# CBASS_MEM_CBASS_FW_45040000h register map
Vendor: Texas Instruments
Peripheral module from a debugger description file (folder AM275x).
Registers are 32-bit, read-write, reset 0x0 unless marked. A register's access mark holds for its fields unless they carry their own. Offsets are as the file gives them; lines under a group give offsets from that group; [hi:lo] are bit positions; {n}, {i} and the like mark numbered series; 'fields as' and 'values as' point back to an identical list; <NAME> marks a mode.

## cbass_fw
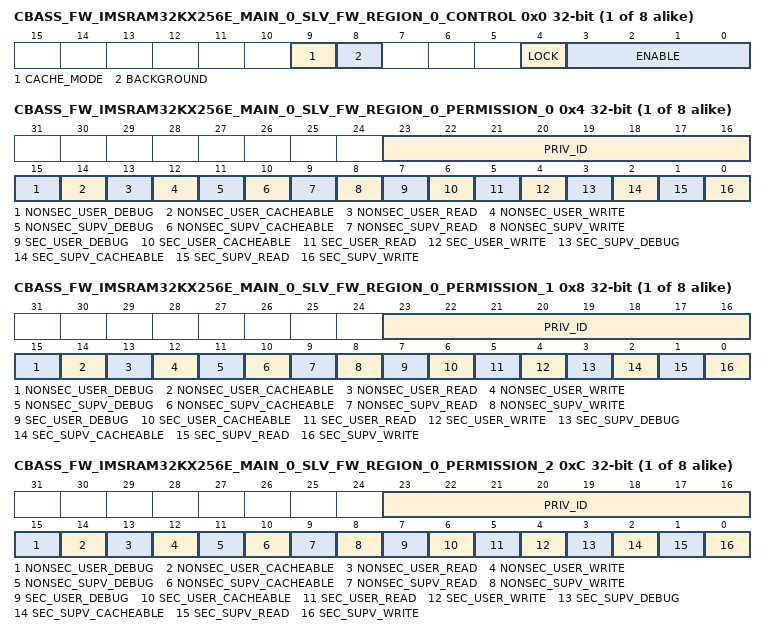
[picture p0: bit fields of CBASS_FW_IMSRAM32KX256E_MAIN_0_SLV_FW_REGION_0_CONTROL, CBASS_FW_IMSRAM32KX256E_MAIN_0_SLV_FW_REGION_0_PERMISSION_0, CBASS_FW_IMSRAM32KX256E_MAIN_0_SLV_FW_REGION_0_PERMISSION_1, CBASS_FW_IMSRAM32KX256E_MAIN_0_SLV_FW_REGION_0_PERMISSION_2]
{0x0+0x20*i} CBASS_FW_IMSRAM32KX256E_MAIN_0_SLV_FW_REGION_{i}_CONTROL access not given (i=0..7) — The FW Region {i} Control Register defines the control fields for the target Imsram32kx256e_main_0.slv region {i} firewall.
  [9] CACHE_MODE rw — Cache mode for region. Set to 1 to check cache permissions. Set to 0 to ignore cache permissions. Reset Source: domain_default_rst_mod_g_rst_n
  [8] BACKGROUND rw — Background enable for region. There can be 1 backgroun region per FW and foreground regions can have overlapping addresses only with the background region. Reset Source: domain_default_rst_mod_g_rst_n
  [4] LOCK — Lock region. Once set region values cannot be modified. Reset Source: domain_default_rst_mod_g_rst_n (access R/W1TS)
  [3:0] ENABLE rw — Enable region. A value of 0xA enables, others disable. Reset Source: domain_default_rst_mod_g_rst_n
{0x4+0x20*i} CBASS_FW_IMSRAM32KX256E_MAIN_0_SLV_FW_REGION_{i}_PERMISSION_0 (i=0..7) — The FW Region {i} Permission 0 Register defines the permissions for the target Imsram32kx256e_main_0.slv region {i} firewall.
  [23:16] PRIV_ID — Allowed privid. Reset Source: domain_default_rst_mod_g_rst_n
  [15] NONSEC_USER_DEBUG — Non-secure user debug allowed. Reset Source: domain_default_rst_mod_g_rst_n
  [14] NONSEC_USER_CACHEABLE — Non-secure user cacheable allowed. Reset Source: domain_default_rst_mod_g_rst_n
  [13] NONSEC_USER_READ — Non-secure user read allowed. Reset Source: domain_default_rst_mod_g_rst_n
  [12] NONSEC_USER_WRITE — Non-secure user write allowed. Reset Source: domain_default_rst_mod_g_rst_n
  [11] NONSEC_SUPV_DEBUG — Non-secure supervisor debug allowed. Reset Source: domain_default_rst_mod_g_rst_n
  [10] NONSEC_SUPV_CACHEABLE — Non-secure supervisor cacheable allowed. Reset Source: domain_default_rst_mod_g_rst_n
  [9] NONSEC_SUPV_READ — Non-secure supervisor read allowed. Reset Source: domain_default_rst_mod_g_rst_n
  [8] NONSEC_SUPV_WRITE — Non-secure supervisor write allowed. Reset Source: domain_default_rst_mod_g_rst_n
  [7] SEC_USER_DEBUG — Secure user debug allowed. Reset Source: domain_default_rst_mod_g_rst_n
  [6] SEC_USER_CACHEABLE — Secure user cacheable allowed. Reset Source: domain_default_rst_mod_g_rst_n
  [5] SEC_USER_READ — Secure user read allowed. Reset Source: domain_default_rst_mod_g_rst_n
  [4] SEC_USER_WRITE — Secure user write allowed. Reset Source: domain_default_rst_mod_g_rst_n
  [3] SEC_SUPV_DEBUG — Secure supervisor debug allowed. Reset Source: domain_default_rst_mod_g_rst_n
  [2] SEC_SUPV_CACHEABLE — Secure supervisor cacheable allowed. Reset Source: domain_default_rst_mod_g_rst_n
  [1] SEC_SUPV_READ — Secure supervisor read allowed. Reset Source: domain_default_rst_mod_g_rst_n
  [0] SEC_SUPV_WRITE — Secure supervisor write allowed. Reset Source: domain_default_rst_mod_g_rst_n
{0x8+0x20*i} CBASS_FW_IMSRAM32KX256E_MAIN_0_SLV_FW_REGION_{i}_PERMISSION_1 (i=0..7) — The FW Region {i} Permission 1 Register defines the permissions for the target Imsram32kx256e_main_0.slv region {i} firewall.
  fields as CBASS_FW_IMSRAM32KX256E_MAIN_0_SLV_FW_REGION_0_PERMISSION_0
{0xC+0x20*i} CBASS_FW_IMSRAM32KX256E_MAIN_0_SLV_FW_REGION_{i}_PERMISSION_2 (i=0..7) — The FW Region {i} Permission 2 Register defines the permissions for the target Imsram32kx256e_main_0.slv region {i} firewall.
  fields as CBASS_FW_IMSRAM32KX256E_MAIN_0_SLV_FW_REGION_0_PERMISSION_0
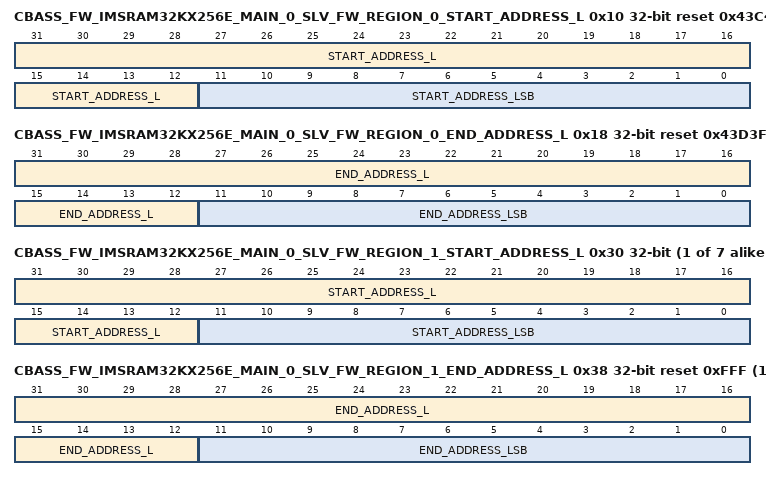
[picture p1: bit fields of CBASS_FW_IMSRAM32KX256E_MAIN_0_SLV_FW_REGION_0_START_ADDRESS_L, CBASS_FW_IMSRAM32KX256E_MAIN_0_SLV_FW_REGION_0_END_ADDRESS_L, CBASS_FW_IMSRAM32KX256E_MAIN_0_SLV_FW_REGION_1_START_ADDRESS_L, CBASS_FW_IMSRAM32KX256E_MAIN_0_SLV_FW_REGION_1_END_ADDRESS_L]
0x10 CBASS_FW_IMSRAM32KX256E_MAIN_0_SLV_FW_REGION_0_START_ADDRESS_L access per field reset 0x43C40000 — The FW Region 0 Start Address Low Register defines the start address bits 31 to 0 for the target Imsram32kx256e_main_0.slv region 0 firewall.
  [31:12] START_ADDRESS_L rw — Start address bits 31 to 12. Lowest 12 bits are forced to 0 as address must be 4KB aligned. Reset Source: domain_default_rst_mod_g_rst_n
  [11:0] START_ADDRESS_LSB ro — Start address bits 11 to 0 are forced to 0 as address must be 4KB aligned. Reset Source: domain_default_rst_mod_g_rst_n
{0x14+0x20*i} CBASS_FW_IMSRAM32KX256E_MAIN_0_SLV_FW_REGION_{i}_START_ADDRESS_H (i=0..7) — The FW Region {i} Start Address High Register defines the start address bits 47 to 32 for the target Imsram32kx256e_main_0.slv region {i} firewall.
  [15:0] START_ADDRESS_H — Start address bits 47 to 32. Reset Source: domain_default_rst_mod_g_rst_n
0x18 CBASS_FW_IMSRAM32KX256E_MAIN_0_SLV_FW_REGION_0_END_ADDRESS_L access per field reset 0x43D3FFFF — The FW Region 0 End Address Low Register defines the end address bits 31 to 0 to include for the target Imsram32kx256e_main_0.slv region 0 firewall.
  [31:12] END_ADDRESS_L rw — End address bits 31 to 12 to include in the match. Lowest 12 bits are forced to 1s as address must be 4KB aligned. Reset Source: domain_default_rst_mod_g_rst_n
  [11:0] END_ADDRESS_LSB ro — End address bits 11 to 0 are forced to 1s as address must be 4KB aligned minus 1. Reset Source: domain_default_rst_mod_g_rst_n
{0x1C+0x20*i} CBASS_FW_IMSRAM32KX256E_MAIN_0_SLV_FW_REGION_{i}_END_ADDRESS_H (i=0..7) — The FW Region {i} End Address High Register defines the end address bits 47 to 32 to include for the target Imsram32kx256e_main_0.slv region {i} firewall.
  [15:0] END_ADDRESS_H — End address bits 47 to 32 to include in the match. Reset Source: domain_default_rst_mod_g_rst_n
{0x10+0x20*i} CBASS_FW_IMSRAM32KX256E_MAIN_0_SLV_FW_REGION_{i}_START_ADDRESS_L access per field (i=1..7) — The FW Region {i} Start Address Low Register defines the start address bits 31 to 0 for the target Imsram32kx256e_main_0.slv region {i} firewall.
  fields as CBASS_FW_IMSRAM32KX256E_MAIN_0_SLV_FW_REGION_0_START_ADDRESS_L
{0x18+0x20*i} CBASS_FW_IMSRAM32KX256E_MAIN_0_SLV_FW_REGION_{i}_END_ADDRESS_L access per field reset 0xFFF (i=1..7) — The FW Region {i} End Address Low Register defines the end address bits 31 to 0 to include for the target Imsram32kx256e_main_0.slv region {i} firewall.
  fields as CBASS_FW_IMSRAM32KX256E_MAIN_0_SLV_FW_REGION_0_END_ADDRESS_L
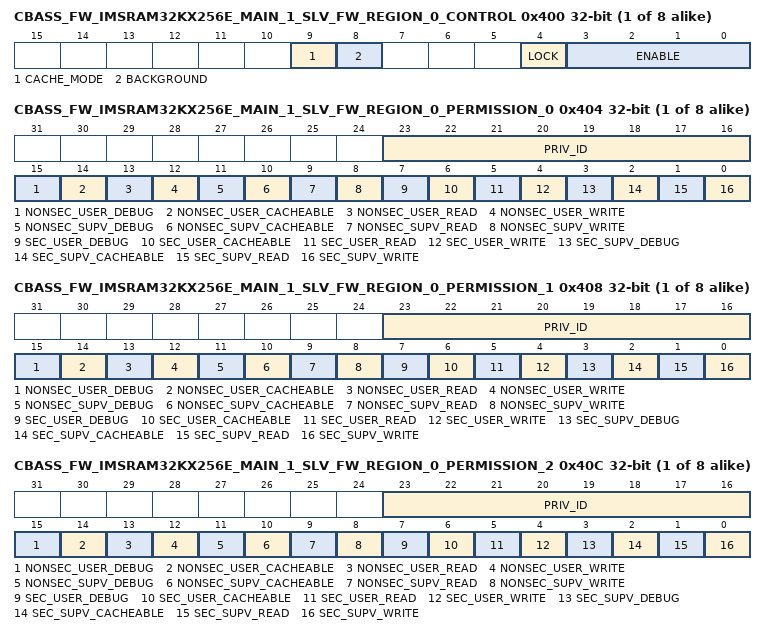
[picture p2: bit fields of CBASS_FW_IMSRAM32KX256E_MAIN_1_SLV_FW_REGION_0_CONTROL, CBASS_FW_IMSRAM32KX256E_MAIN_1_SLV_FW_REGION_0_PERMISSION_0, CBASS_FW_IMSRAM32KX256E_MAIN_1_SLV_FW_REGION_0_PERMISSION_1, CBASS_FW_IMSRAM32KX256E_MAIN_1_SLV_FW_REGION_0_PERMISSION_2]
{0x400+0x20*i} CBASS_FW_IMSRAM32KX256E_MAIN_1_SLV_FW_REGION_{i}_CONTROL access not given (i=0..7) — The FW Region {i} Control Register defines the control fields for the target Imsram32kx256e_main_1.slv region {i} firewall.
  fields as CBASS_FW_IMSRAM32KX256E_MAIN_0_SLV_FW_REGION_0_CONTROL
{0x404+0x20*i} CBASS_FW_IMSRAM32KX256E_MAIN_1_SLV_FW_REGION_{i}_PERMISSION_0 (i=0..7) — The FW Region {i} Permission 0 Register defines the permissions for the target Imsram32kx256e_main_1.slv region {i} firewall.
  fields as CBASS_FW_IMSRAM32KX256E_MAIN_0_SLV_FW_REGION_0_PERMISSION_0
{0x408+0x20*i} CBASS_FW_IMSRAM32KX256E_MAIN_1_SLV_FW_REGION_{i}_PERMISSION_1 (i=0..7) — The FW Region {i} Permission 1 Register defines the permissions for the target Imsram32kx256e_main_1.slv region {i} firewall.
  fields as CBASS_FW_IMSRAM32KX256E_MAIN_0_SLV_FW_REGION_0_PERMISSION_0
{0x40C+0x20*i} CBASS_FW_IMSRAM32KX256E_MAIN_1_SLV_FW_REGION_{i}_PERMISSION_2 (i=0..7) — The FW Region {i} Permission 2 Register defines the permissions for the target Imsram32kx256e_main_1.slv region {i} firewall.
  fields as CBASS_FW_IMSRAM32KX256E_MAIN_0_SLV_FW_REGION_0_PERMISSION_0
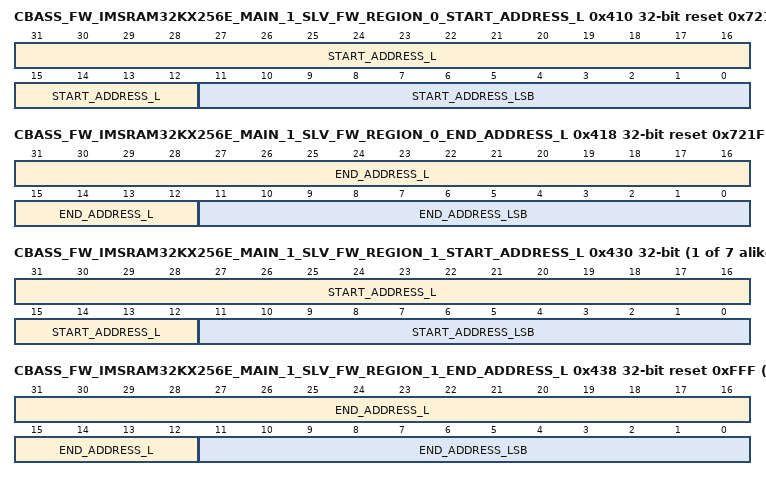
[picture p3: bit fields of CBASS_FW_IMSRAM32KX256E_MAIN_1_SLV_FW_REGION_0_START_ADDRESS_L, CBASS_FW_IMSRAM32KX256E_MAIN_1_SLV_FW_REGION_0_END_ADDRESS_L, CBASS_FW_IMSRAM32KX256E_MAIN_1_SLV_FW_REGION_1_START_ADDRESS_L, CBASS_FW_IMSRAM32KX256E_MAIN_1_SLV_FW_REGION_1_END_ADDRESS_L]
0x410 CBASS_FW_IMSRAM32KX256E_MAIN_1_SLV_FW_REGION_0_START_ADDRESS_L access per field reset 0x72100000 — The FW Region 0 Start Address Low Register defines the start address bits 31 to 0 for the target Imsram32kx256e_main_1.slv region 0 firewall.
  fields as CBASS_FW_IMSRAM32KX256E_MAIN_0_SLV_FW_REGION_0_START_ADDRESS_L
{0x414+0x20*i} CBASS_FW_IMSRAM32KX256E_MAIN_1_SLV_FW_REGION_{i}_START_ADDRESS_H (i=0..7) — The FW Region {i} Start Address High Register defines the start address bits 47 to 32 for the target Imsram32kx256e_main_1.slv region {i} firewall.
  fields as CBASS_FW_IMSRAM32KX256E_MAIN_0_SLV_FW_REGION_0_START_ADDRESS_H
0x418 CBASS_FW_IMSRAM32KX256E_MAIN_1_SLV_FW_REGION_0_END_ADDRESS_L access per field reset 0x721FFFFF — The FW Region 0 End Address Low Register defines the end address bits 31 to 0 to include for the target Imsram32kx256e_main_1.slv region 0 firewall.
  fields as CBASS_FW_IMSRAM32KX256E_MAIN_0_SLV_FW_REGION_0_END_ADDRESS_L
{0x41C+0x20*i} CBASS_FW_IMSRAM32KX256E_MAIN_1_SLV_FW_REGION_{i}_END_ADDRESS_H (i=0..7) — The FW Region {i} End Address High Register defines the end address bits 47 to 32 to include for the target Imsram32kx256e_main_1.slv region {i} firewall.
  fields as CBASS_FW_IMSRAM32KX256E_MAIN_0_SLV_FW_REGION_0_END_ADDRESS_H
{0x410+0x20*i} CBASS_FW_IMSRAM32KX256E_MAIN_1_SLV_FW_REGION_{i}_START_ADDRESS_L access per field (i=1..7) — The FW Region {i} Start Address Low Register defines the start address bits 31 to 0 for the target Imsram32kx256e_main_1.slv region {i} firewall.
  fields as CBASS_FW_IMSRAM32KX256E_MAIN_0_SLV_FW_REGION_0_START_ADDRESS_L
{0x418+0x20*i} CBASS_FW_IMSRAM32KX256E_MAIN_1_SLV_FW_REGION_{i}_END_ADDRESS_L access per field reset 0xFFF (i=1..7) — The FW Region {i} End Address Low Register defines the end address bits 31 to 0 to include for the target Imsram32kx256e_main_1.slv region {i} firewall.
  fields as CBASS_FW_IMSRAM32KX256E_MAIN_0_SLV_FW_REGION_0_END_ADDRESS_L
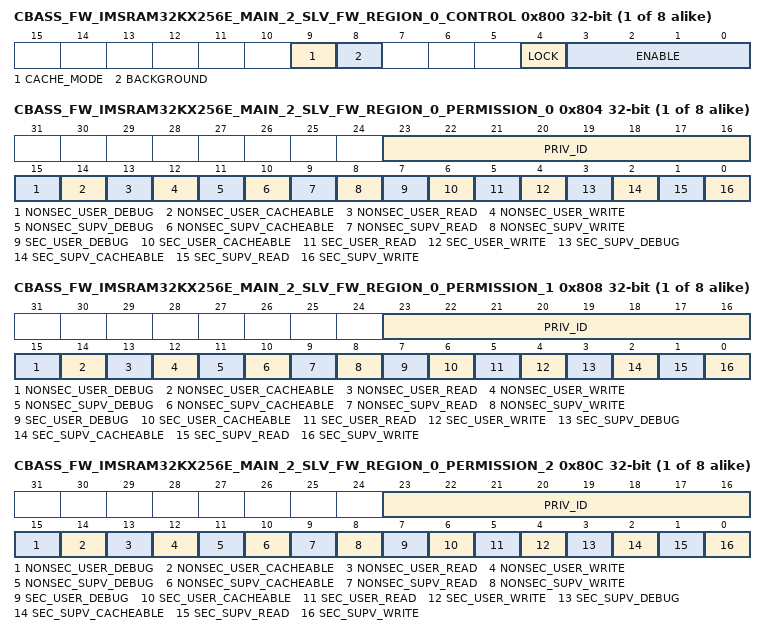
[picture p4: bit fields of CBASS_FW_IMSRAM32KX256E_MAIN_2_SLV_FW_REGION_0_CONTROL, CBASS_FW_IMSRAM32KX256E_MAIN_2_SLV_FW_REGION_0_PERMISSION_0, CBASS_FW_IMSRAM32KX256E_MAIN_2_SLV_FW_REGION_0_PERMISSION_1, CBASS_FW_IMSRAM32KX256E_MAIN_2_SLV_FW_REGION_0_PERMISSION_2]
{0x800+0x20*i} CBASS_FW_IMSRAM32KX256E_MAIN_2_SLV_FW_REGION_{i}_CONTROL access not given (i=0..7) — The FW Region {i} Control Register defines the control fields for the target Imsram32kx256e_main_2.slv region {i} firewall.
  fields as CBASS_FW_IMSRAM32KX256E_MAIN_0_SLV_FW_REGION_0_CONTROL
{0x804+0x20*i} CBASS_FW_IMSRAM32KX256E_MAIN_2_SLV_FW_REGION_{i}_PERMISSION_0 (i=0..7) — The FW Region {i} Permission 0 Register defines the permissions for the target Imsram32kx256e_main_2.slv region {i} firewall.
  fields as CBASS_FW_IMSRAM32KX256E_MAIN_0_SLV_FW_REGION_0_PERMISSION_0
{0x808+0x20*i} CBASS_FW_IMSRAM32KX256E_MAIN_2_SLV_FW_REGION_{i}_PERMISSION_1 (i=0..7) — The FW Region {i} Permission 1 Register defines the permissions for the target Imsram32kx256e_main_2.slv region {i} firewall.
  fields as CBASS_FW_IMSRAM32KX256E_MAIN_0_SLV_FW_REGION_0_PERMISSION_0
{0x80C+0x20*i} CBASS_FW_IMSRAM32KX256E_MAIN_2_SLV_FW_REGION_{i}_PERMISSION_2 (i=0..7) — The FW Region {i} Permission 2 Register defines the permissions for the target Imsram32kx256e_main_2.slv region {i} firewall.
  fields as CBASS_FW_IMSRAM32KX256E_MAIN_0_SLV_FW_REGION_0_PERMISSION_0
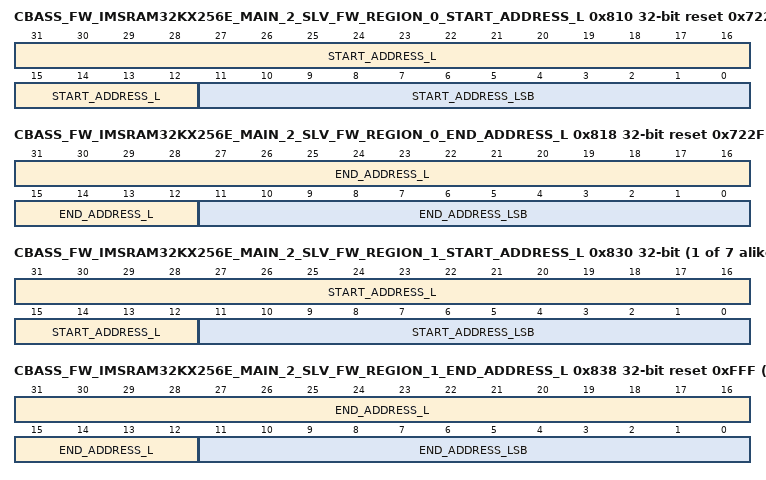
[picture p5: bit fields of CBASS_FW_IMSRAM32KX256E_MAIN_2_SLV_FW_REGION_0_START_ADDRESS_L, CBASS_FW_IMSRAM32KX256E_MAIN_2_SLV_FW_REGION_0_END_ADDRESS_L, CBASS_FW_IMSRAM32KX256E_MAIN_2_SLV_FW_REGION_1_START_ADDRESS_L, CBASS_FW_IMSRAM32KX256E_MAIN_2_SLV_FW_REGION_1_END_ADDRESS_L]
0x810 CBASS_FW_IMSRAM32KX256E_MAIN_2_SLV_FW_REGION_0_START_ADDRESS_L access per field reset 0x72200000 — The FW Region 0 Start Address Low Register defines the start address bits 31 to 0 for the target Imsram32kx256e_main_2.slv region 0 firewall.
  fields as CBASS_FW_IMSRAM32KX256E_MAIN_0_SLV_FW_REGION_0_START_ADDRESS_L
{0x814+0x20*i} CBASS_FW_IMSRAM32KX256E_MAIN_2_SLV_FW_REGION_{i}_START_ADDRESS_H (i=0..7) — The FW Region {i} Start Address High Register defines the start address bits 47 to 32 for the target Imsram32kx256e_main_2.slv region {i} firewall.
  fields as CBASS_FW_IMSRAM32KX256E_MAIN_0_SLV_FW_REGION_0_START_ADDRESS_H
0x818 CBASS_FW_IMSRAM32KX256E_MAIN_2_SLV_FW_REGION_0_END_ADDRESS_L access per field reset 0x722FFFFF — The FW Region 0 End Address Low Register defines the end address bits 31 to 0 to include for the target Imsram32kx256e_main_2.slv region 0 firewall.
  fields as CBASS_FW_IMSRAM32KX256E_MAIN_0_SLV_FW_REGION_0_END_ADDRESS_L
{0x81C+0x20*i} CBASS_FW_IMSRAM32KX256E_MAIN_2_SLV_FW_REGION_{i}_END_ADDRESS_H (i=0..7) — The FW Region {i} End Address High Register defines the end address bits 47 to 32 to include for the target Imsram32kx256e_main_2.slv region {i} firewall.
  fields as CBASS_FW_IMSRAM32KX256E_MAIN_0_SLV_FW_REGION_0_END_ADDRESS_H
{0x810+0x20*i} CBASS_FW_IMSRAM32KX256E_MAIN_2_SLV_FW_REGION_{i}_START_ADDRESS_L access per field (i=1..7) — The FW Region {i} Start Address Low Register defines the start address bits 31 to 0 for the target Imsram32kx256e_main_2.slv region {i} firewall.
  fields as CBASS_FW_IMSRAM32KX256E_MAIN_0_SLV_FW_REGION_0_START_ADDRESS_L
{0x818+0x20*i} CBASS_FW_IMSRAM32KX256E_MAIN_2_SLV_FW_REGION_{i}_END_ADDRESS_L access per field reset 0xFFF (i=1..7) — The FW Region {i} End Address Low Register defines the end address bits 31 to 0 to include for the target Imsram32kx256e_main_2.slv region {i} firewall.
  fields as CBASS_FW_IMSRAM32KX256E_MAIN_0_SLV_FW_REGION_0_END_ADDRESS_L
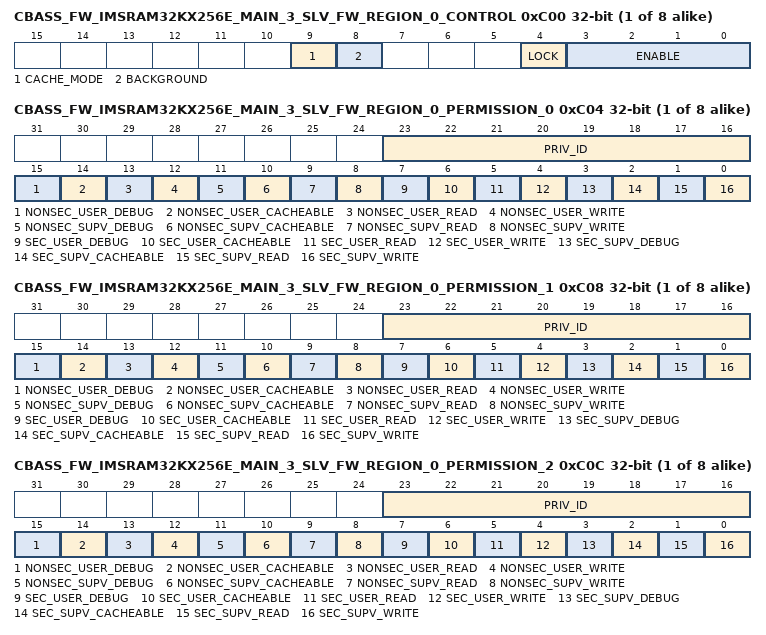
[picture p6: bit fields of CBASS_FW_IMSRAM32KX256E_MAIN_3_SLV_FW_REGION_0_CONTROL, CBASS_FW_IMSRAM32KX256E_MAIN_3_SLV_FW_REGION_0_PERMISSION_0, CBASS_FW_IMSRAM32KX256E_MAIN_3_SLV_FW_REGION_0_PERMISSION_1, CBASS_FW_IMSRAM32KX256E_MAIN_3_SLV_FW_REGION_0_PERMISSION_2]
{0xC00+0x20*i} CBASS_FW_IMSRAM32KX256E_MAIN_3_SLV_FW_REGION_{i}_CONTROL access not given (i=0..7) — The FW Region {i} Control Register defines the control fields for the target Imsram32kx256e_main_3.slv region {i} firewall.
  fields as CBASS_FW_IMSRAM32KX256E_MAIN_0_SLV_FW_REGION_0_CONTROL
{0xC04+0x20*i} CBASS_FW_IMSRAM32KX256E_MAIN_3_SLV_FW_REGION_{i}_PERMISSION_0 (i=0..7) — The FW Region {i} Permission 0 Register defines the permissions for the target Imsram32kx256e_main_3.slv region {i} firewall.
  fields as CBASS_FW_IMSRAM32KX256E_MAIN_0_SLV_FW_REGION_0_PERMISSION_0
{0xC08+0x20*i} CBASS_FW_IMSRAM32KX256E_MAIN_3_SLV_FW_REGION_{i}_PERMISSION_1 (i=0..7) — The FW Region {i} Permission 1 Register defines the permissions for the target Imsram32kx256e_main_3.slv region {i} firewall.
  fields as CBASS_FW_IMSRAM32KX256E_MAIN_0_SLV_FW_REGION_0_PERMISSION_0
{0xC0C+0x20*i} CBASS_FW_IMSRAM32KX256E_MAIN_3_SLV_FW_REGION_{i}_PERMISSION_2 (i=0..7) — The FW Region {i} Permission 2 Register defines the permissions for the target Imsram32kx256e_main_3.slv region {i} firewall.
  fields as CBASS_FW_IMSRAM32KX256E_MAIN_0_SLV_FW_REGION_0_PERMISSION_0
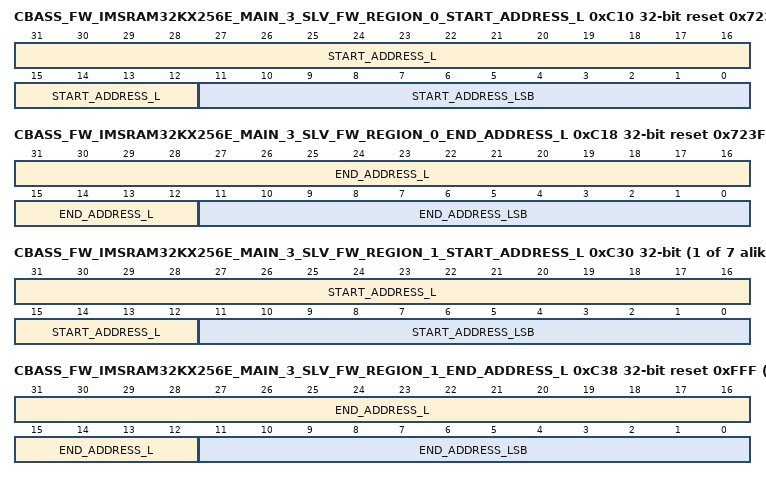
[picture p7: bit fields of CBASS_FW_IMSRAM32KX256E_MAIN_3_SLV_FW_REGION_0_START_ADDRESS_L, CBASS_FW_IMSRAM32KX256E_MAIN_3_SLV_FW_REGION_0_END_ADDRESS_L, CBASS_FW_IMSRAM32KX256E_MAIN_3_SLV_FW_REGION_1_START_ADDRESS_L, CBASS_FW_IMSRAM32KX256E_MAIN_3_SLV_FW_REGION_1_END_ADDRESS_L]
0xC10 CBASS_FW_IMSRAM32KX256E_MAIN_3_SLV_FW_REGION_0_START_ADDRESS_L access per field reset 0x72300000 — The FW Region 0 Start Address Low Register defines the start address bits 31 to 0 for the target Imsram32kx256e_main_3.slv region 0 firewall.
  fields as CBASS_FW_IMSRAM32KX256E_MAIN_0_SLV_FW_REGION_0_START_ADDRESS_L
{0xC14+0x20*i} CBASS_FW_IMSRAM32KX256E_MAIN_3_SLV_FW_REGION_{i}_START_ADDRESS_H (i=0..7) — The FW Region {i} Start Address High Register defines the start address bits 47 to 32 for the target Imsram32kx256e_main_3.slv region {i} firewall.
  fields as CBASS_FW_IMSRAM32KX256E_MAIN_0_SLV_FW_REGION_0_START_ADDRESS_H
0xC18 CBASS_FW_IMSRAM32KX256E_MAIN_3_SLV_FW_REGION_0_END_ADDRESS_L access per field reset 0x723FFFFF — The FW Region 0 End Address Low Register defines the end address bits 31 to 0 to include for the target Imsram32kx256e_main_3.slv region 0 firewall.
  fields as CBASS_FW_IMSRAM32KX256E_MAIN_0_SLV_FW_REGION_0_END_ADDRESS_L
{0xC1C+0x20*i} CBASS_FW_IMSRAM32KX256E_MAIN_3_SLV_FW_REGION_{i}_END_ADDRESS_H (i=0..7) — The FW Region {i} End Address High Register defines the end address bits 47 to 32 to include for the target Imsram32kx256e_main_3.slv region {i} firewall.
  fields as CBASS_FW_IMSRAM32KX256E_MAIN_0_SLV_FW_REGION_0_END_ADDRESS_H
{0xC10+0x20*i} CBASS_FW_IMSRAM32KX256E_MAIN_3_SLV_FW_REGION_{i}_START_ADDRESS_L access per field (i=1..7) — The FW Region {i} Start Address Low Register defines the start address bits 31 to 0 for the target Imsram32kx256e_main_3.slv region {i} firewall.
  fields as CBASS_FW_IMSRAM32KX256E_MAIN_0_SLV_FW_REGION_0_START_ADDRESS_L
{0xC18+0x20*i} CBASS_FW_IMSRAM32KX256E_MAIN_3_SLV_FW_REGION_{i}_END_ADDRESS_L access per field reset 0xFFF (i=1..7) — The FW Region {i} End Address Low Register defines the end address bits 31 to 0 to include for the target Imsram32kx256e_main_3.slv region {i} firewall.
  fields as CBASS_FW_IMSRAM32KX256E_MAIN_0_SLV_FW_REGION_0_END_ADDRESS_L
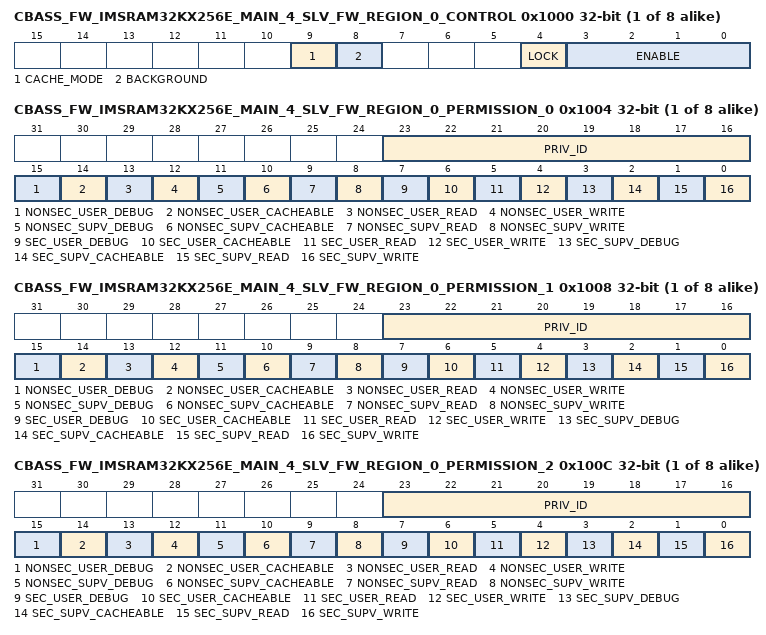
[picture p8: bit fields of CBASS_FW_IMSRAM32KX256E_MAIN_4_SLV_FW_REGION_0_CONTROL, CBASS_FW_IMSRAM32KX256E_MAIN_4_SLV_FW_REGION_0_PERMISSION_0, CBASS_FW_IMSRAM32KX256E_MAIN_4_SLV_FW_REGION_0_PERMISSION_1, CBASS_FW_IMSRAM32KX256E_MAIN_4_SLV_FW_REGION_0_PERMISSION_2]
{0x1000+0x20*i} CBASS_FW_IMSRAM32KX256E_MAIN_4_SLV_FW_REGION_{i}_CONTROL access not given (i=0..7) — The FW Region {i} Control Register defines the control fields for the target Imsram32kx256e_main_4.slv region {i} firewall.
  fields as CBASS_FW_IMSRAM32KX256E_MAIN_0_SLV_FW_REGION_0_CONTROL
{0x1004+0x20*i} CBASS_FW_IMSRAM32KX256E_MAIN_4_SLV_FW_REGION_{i}_PERMISSION_0 (i=0..7) — The FW Region {i} Permission 0 Register defines the permissions for the target Imsram32kx256e_main_4.slv region {i} firewall.
  fields as CBASS_FW_IMSRAM32KX256E_MAIN_0_SLV_FW_REGION_0_PERMISSION_0
{0x1008+0x20*i} CBASS_FW_IMSRAM32KX256E_MAIN_4_SLV_FW_REGION_{i}_PERMISSION_1 (i=0..7) — The FW Region {i} Permission 1 Register defines the permissions for the target Imsram32kx256e_main_4.slv region {i} firewall.
  fields as CBASS_FW_IMSRAM32KX256E_MAIN_0_SLV_FW_REGION_0_PERMISSION_0
{0x100C+0x20*i} CBASS_FW_IMSRAM32KX256E_MAIN_4_SLV_FW_REGION_{i}_PERMISSION_2 (i=0..7) — The FW Region {i} Permission 2 Register defines the permissions for the target Imsram32kx256e_main_4.slv region {i} firewall.
  fields as CBASS_FW_IMSRAM32KX256E_MAIN_0_SLV_FW_REGION_0_PERMISSION_0
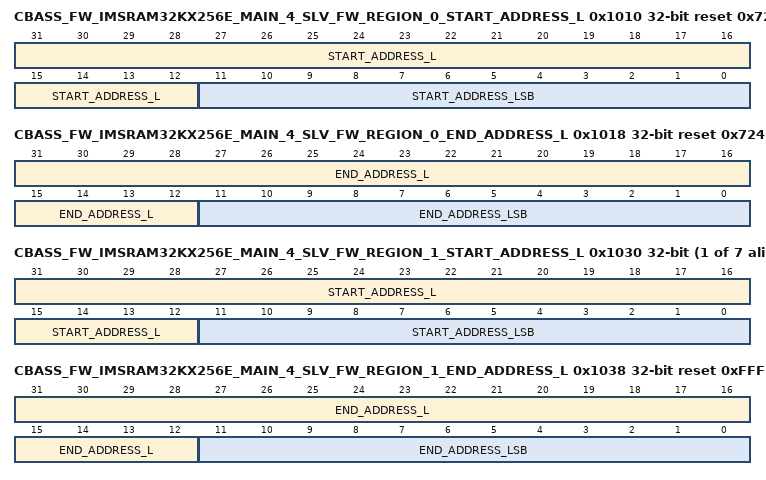
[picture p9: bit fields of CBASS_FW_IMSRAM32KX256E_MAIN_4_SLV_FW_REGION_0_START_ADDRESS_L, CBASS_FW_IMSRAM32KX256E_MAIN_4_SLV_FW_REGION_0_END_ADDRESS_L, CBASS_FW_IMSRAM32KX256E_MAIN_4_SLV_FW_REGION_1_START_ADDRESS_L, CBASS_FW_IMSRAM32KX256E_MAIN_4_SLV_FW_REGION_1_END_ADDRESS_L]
0x1010 CBASS_FW_IMSRAM32KX256E_MAIN_4_SLV_FW_REGION_0_START_ADDRESS_L access per field reset 0x72400000 — The FW Region 0 Start Address Low Register defines the start address bits 31 to 0 for the target Imsram32kx256e_main_4.slv region 0 firewall.
  fields as CBASS_FW_IMSRAM32KX256E_MAIN_0_SLV_FW_REGION_0_START_ADDRESS_L
{0x1014+0x20*i} CBASS_FW_IMSRAM32KX256E_MAIN_4_SLV_FW_REGION_{i}_START_ADDRESS_H (i=0..7) — The FW Region {i} Start Address High Register defines the start address bits 47 to 32 for the target Imsram32kx256e_main_4.slv region {i} firewall.
  fields as CBASS_FW_IMSRAM32KX256E_MAIN_0_SLV_FW_REGION_0_START_ADDRESS_H
0x1018 CBASS_FW_IMSRAM32KX256E_MAIN_4_SLV_FW_REGION_0_END_ADDRESS_L access per field reset 0x724FFFFF — The FW Region 0 End Address Low Register defines the end address bits 31 to 0 to include for the target Imsram32kx256e_main_4.slv region 0 firewall.
  fields as CBASS_FW_IMSRAM32KX256E_MAIN_0_SLV_FW_REGION_0_END_ADDRESS_L
{0x101C+0x20*i} CBASS_FW_IMSRAM32KX256E_MAIN_4_SLV_FW_REGION_{i}_END_ADDRESS_H (i=0..7) — The FW Region {i} End Address High Register defines the end address bits 47 to 32 to include for the target Imsram32kx256e_main_4.slv region {i} firewall.
  fields as CBASS_FW_IMSRAM32KX256E_MAIN_0_SLV_FW_REGION_0_END_ADDRESS_H
{0x1010+0x20*i} CBASS_FW_IMSRAM32KX256E_MAIN_4_SLV_FW_REGION_{i}_START_ADDRESS_L access per field (i=1..7) — The FW Region {i} Start Address Low Register defines the start address bits 31 to 0 for the target Imsram32kx256e_main_4.slv region {i} firewall.
  fields as CBASS_FW_IMSRAM32KX256E_MAIN_0_SLV_FW_REGION_0_START_ADDRESS_L
{0x1018+0x20*i} CBASS_FW_IMSRAM32KX256E_MAIN_4_SLV_FW_REGION_{i}_END_ADDRESS_L access per field reset 0xFFF (i=1..7) — The FW Region {i} End Address Low Register defines the end address bits 31 to 0 to include for the target Imsram32kx256e_main_4.slv region {i} firewall.
  fields as CBASS_FW_IMSRAM32KX256E_MAIN_0_SLV_FW_REGION_0_END_ADDRESS_L
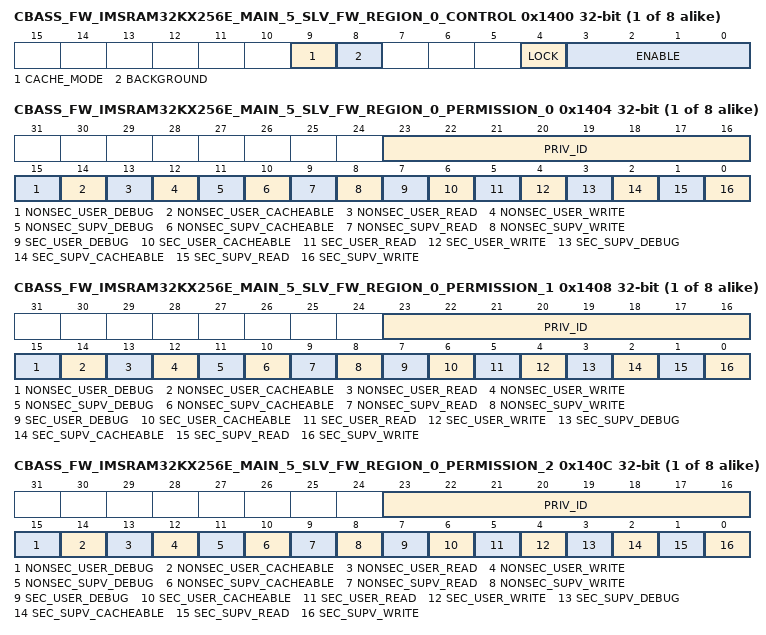
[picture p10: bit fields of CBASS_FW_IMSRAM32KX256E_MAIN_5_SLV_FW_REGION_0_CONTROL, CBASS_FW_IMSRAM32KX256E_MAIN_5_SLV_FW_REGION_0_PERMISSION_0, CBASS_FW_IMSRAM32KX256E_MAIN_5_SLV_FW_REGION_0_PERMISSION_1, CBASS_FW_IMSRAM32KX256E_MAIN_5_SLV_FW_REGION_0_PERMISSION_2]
{0x1400+0x20*i} CBASS_FW_IMSRAM32KX256E_MAIN_5_SLV_FW_REGION_{i}_CONTROL access not given (i=0..7) — The FW Region {i} Control Register defines the control fields for the target Imsram32kx256e_main_5.slv region {i} firewall.
  fields as CBASS_FW_IMSRAM32KX256E_MAIN_0_SLV_FW_REGION_0_CONTROL
{0x1404+0x20*i} CBASS_FW_IMSRAM32KX256E_MAIN_5_SLV_FW_REGION_{i}_PERMISSION_0 (i=0..7) — The FW Region {i} Permission 0 Register defines the permissions for the target Imsram32kx256e_main_5.slv region {i} firewall.
  fields as CBASS_FW_IMSRAM32KX256E_MAIN_0_SLV_FW_REGION_0_PERMISSION_0
{0x1408+0x20*i} CBASS_FW_IMSRAM32KX256E_MAIN_5_SLV_FW_REGION_{i}_PERMISSION_1 (i=0..7) — The FW Region {i} Permission 1 Register defines the permissions for the target Imsram32kx256e_main_5.slv region {i} firewall.
  fields as CBASS_FW_IMSRAM32KX256E_MAIN_0_SLV_FW_REGION_0_PERMISSION_0
{0x140C+0x20*i} CBASS_FW_IMSRAM32KX256E_MAIN_5_SLV_FW_REGION_{i}_PERMISSION_2 (i=0..7) — The FW Region {i} Permission 2 Register defines the permissions for the target Imsram32kx256e_main_5.slv region {i} firewall.
  fields as CBASS_FW_IMSRAM32KX256E_MAIN_0_SLV_FW_REGION_0_PERMISSION_0
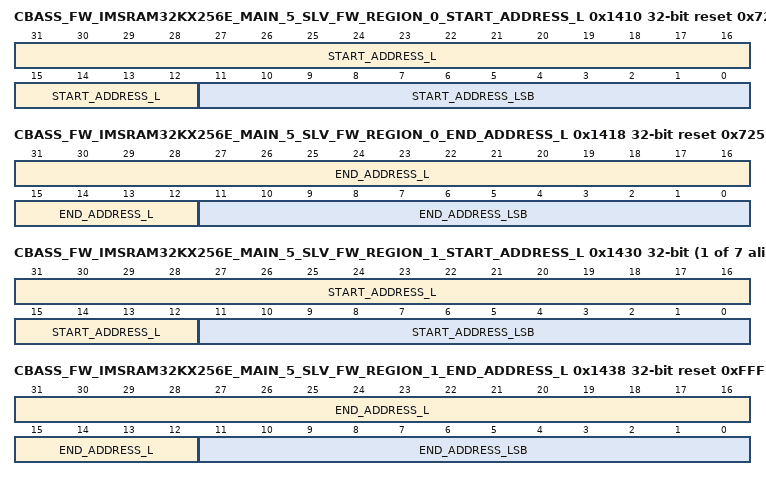
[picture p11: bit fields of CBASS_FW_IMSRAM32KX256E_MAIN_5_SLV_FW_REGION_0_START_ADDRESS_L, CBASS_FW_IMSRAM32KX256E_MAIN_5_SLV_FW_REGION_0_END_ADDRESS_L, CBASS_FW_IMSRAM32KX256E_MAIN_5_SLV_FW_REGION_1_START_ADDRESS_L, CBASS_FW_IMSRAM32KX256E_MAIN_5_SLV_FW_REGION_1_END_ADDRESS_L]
0x1410 CBASS_FW_IMSRAM32KX256E_MAIN_5_SLV_FW_REGION_0_START_ADDRESS_L access per field reset 0x72500000 — The FW Region 0 Start Address Low Register defines the start address bits 31 to 0 for the target Imsram32kx256e_main_5.slv region 0 firewall.
  fields as CBASS_FW_IMSRAM32KX256E_MAIN_0_SLV_FW_REGION_0_START_ADDRESS_L
{0x1414+0x20*i} CBASS_FW_IMSRAM32KX256E_MAIN_5_SLV_FW_REGION_{i}_START_ADDRESS_H (i=0..7) — The FW Region {i} Start Address High Register defines the start address bits 47 to 32 for the target Imsram32kx256e_main_5.slv region {i} firewall.
  fields as CBASS_FW_IMSRAM32KX256E_MAIN_0_SLV_FW_REGION_0_START_ADDRESS_H
0x1418 CBASS_FW_IMSRAM32KX256E_MAIN_5_SLV_FW_REGION_0_END_ADDRESS_L access per field reset 0x725FFFFF — The FW Region 0 End Address Low Register defines the end address bits 31 to 0 to include for the target Imsram32kx256e_main_5.slv region 0 firewall.
  fields as CBASS_FW_IMSRAM32KX256E_MAIN_0_SLV_FW_REGION_0_END_ADDRESS_L
{0x141C+0x20*i} CBASS_FW_IMSRAM32KX256E_MAIN_5_SLV_FW_REGION_{i}_END_ADDRESS_H (i=0..7) — The FW Region {i} End Address High Register defines the end address bits 47 to 32 to include for the target Imsram32kx256e_main_5.slv region {i} firewall.
  fields as CBASS_FW_IMSRAM32KX256E_MAIN_0_SLV_FW_REGION_0_END_ADDRESS_H
{0x1410+0x20*i} CBASS_FW_IMSRAM32KX256E_MAIN_5_SLV_FW_REGION_{i}_START_ADDRESS_L access per field (i=1..7) — The FW Region {i} Start Address Low Register defines the start address bits 31 to 0 for the target Imsram32kx256e_main_5.slv region {i} firewall.
  fields as CBASS_FW_IMSRAM32KX256E_MAIN_0_SLV_FW_REGION_0_START_ADDRESS_L
{0x1418+0x20*i} CBASS_FW_IMSRAM32KX256E_MAIN_5_SLV_FW_REGION_{i}_END_ADDRESS_L access per field reset 0xFFF (i=1..7) — The FW Region {i} End Address Low Register defines the end address bits 31 to 0 to include for the target Imsram32kx256e_main_5.slv region {i} firewall.
  fields as CBASS_FW_IMSRAM32KX256E_MAIN_0_SLV_FW_REGION_0_END_ADDRESS_L
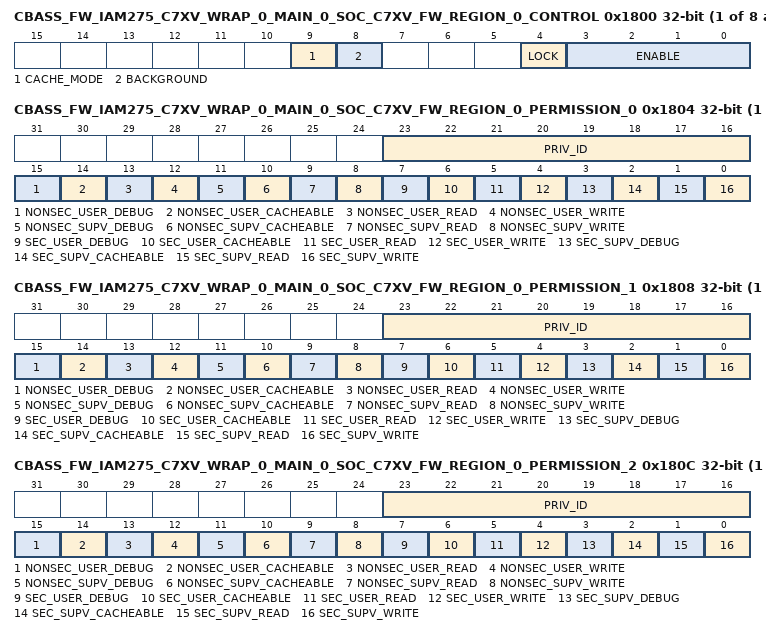
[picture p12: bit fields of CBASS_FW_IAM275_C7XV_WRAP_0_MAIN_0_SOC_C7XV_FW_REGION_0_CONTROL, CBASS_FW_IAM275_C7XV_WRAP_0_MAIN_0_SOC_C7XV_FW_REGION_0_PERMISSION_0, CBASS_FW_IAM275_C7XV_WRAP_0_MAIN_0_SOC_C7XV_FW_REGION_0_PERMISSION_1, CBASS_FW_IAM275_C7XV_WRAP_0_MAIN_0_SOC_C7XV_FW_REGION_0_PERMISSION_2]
{0x1800+0x20*i} CBASS_FW_IAM275_C7XV_WRAP_0_MAIN_0_SOC_C7XV_FW_REGION_{i}_CONTROL access not given (i=0..7) — The FW Region {i} Control Register defines the control fields for the target Iam275_c7xv_wrap_0_main_0.soc_c7xv region {i} firewall.
  fields as CBASS_FW_IMSRAM32KX256E_MAIN_0_SLV_FW_REGION_0_CONTROL
{0x1804+0x20*i} CBASS_FW_IAM275_C7XV_WRAP_0_MAIN_0_SOC_C7XV_FW_REGION_{i}_PERMISSION_0 (i=0..7) — The FW Region {i} Permission 0 Register defines the permissions for the target Iam275_c7xv_wrap_0_main_0.soc_c7xv region {i} firewall.
  fields as CBASS_FW_IMSRAM32KX256E_MAIN_0_SLV_FW_REGION_0_PERMISSION_0
{0x1808+0x20*i} CBASS_FW_IAM275_C7XV_WRAP_0_MAIN_0_SOC_C7XV_FW_REGION_{i}_PERMISSION_1 (i=0..7) — The FW Region {i} Permission 1 Register defines the permissions for the target Iam275_c7xv_wrap_0_main_0.soc_c7xv region {i} firewall.
  fields as CBASS_FW_IMSRAM32KX256E_MAIN_0_SLV_FW_REGION_0_PERMISSION_0
{0x180C+0x20*i} CBASS_FW_IAM275_C7XV_WRAP_0_MAIN_0_SOC_C7XV_FW_REGION_{i}_PERMISSION_2 (i=0..7) — The FW Region {i} Permission 2 Register defines the permissions for the target Iam275_c7xv_wrap_0_main_0.soc_c7xv region {i} firewall.
  fields as CBASS_FW_IMSRAM32KX256E_MAIN_0_SLV_FW_REGION_0_PERMISSION_0
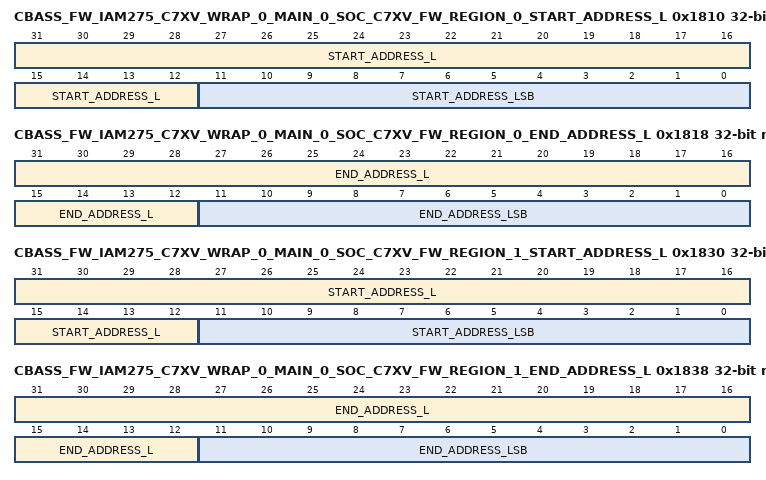
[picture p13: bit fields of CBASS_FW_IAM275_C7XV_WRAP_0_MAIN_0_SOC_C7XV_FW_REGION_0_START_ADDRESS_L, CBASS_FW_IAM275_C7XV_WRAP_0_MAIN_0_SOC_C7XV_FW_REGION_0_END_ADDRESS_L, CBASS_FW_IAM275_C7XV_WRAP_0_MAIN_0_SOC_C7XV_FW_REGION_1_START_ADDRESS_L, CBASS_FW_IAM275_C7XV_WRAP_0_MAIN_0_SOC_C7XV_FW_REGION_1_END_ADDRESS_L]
0x1810 CBASS_FW_IAM275_C7XV_WRAP_0_MAIN_0_SOC_C7XV_FW_REGION_0_START_ADDRESS_L access per field reset 0x7E000000 — The FW Region 0 Start Address Low Register defines the start address bits 31 to 0 for the target Iam275_c7xv_wrap_0_main_0.soc_c7xv region 0 firewall.
  fields as CBASS_FW_IMSRAM32KX256E_MAIN_0_SLV_FW_REGION_0_START_ADDRESS_L
{0x1814+0x20*i} CBASS_FW_IAM275_C7XV_WRAP_0_MAIN_0_SOC_C7XV_FW_REGION_{i}_START_ADDRESS_H (i=0..7) — The FW Region {i} Start Address High Register defines the start address bits 47 to 32 for the target Iam275_c7xv_wrap_0_main_0.soc_c7xv region {i} firewall.
  fields as CBASS_FW_IMSRAM32KX256E_MAIN_0_SLV_FW_REGION_0_START_ADDRESS_H
0x1818 CBASS_FW_IAM275_C7XV_WRAP_0_MAIN_0_SOC_C7XV_FW_REGION_0_END_ADDRESS_L access per field reset 0x7E1FFFFF — The FW Region 0 End Address Low Register defines the end address bits 31 to 0 to include for the target Iam275_c7xv_wrap_0_main_0.soc_c7xv region 0 firewall.
  fields as CBASS_FW_IMSRAM32KX256E_MAIN_0_SLV_FW_REGION_0_END_ADDRESS_L
{0x181C+0x20*i} CBASS_FW_IAM275_C7XV_WRAP_0_MAIN_0_SOC_C7XV_FW_REGION_{i}_END_ADDRESS_H (i=0..7) — The FW Region {i} End Address High Register defines the end address bits 47 to 32 to include for the target Iam275_c7xv_wrap_0_main_0.soc_c7xv region {i} firewall.
  fields as CBASS_FW_IMSRAM32KX256E_MAIN_0_SLV_FW_REGION_0_END_ADDRESS_H
0x1830 CBASS_FW_IAM275_C7XV_WRAP_0_MAIN_0_SOC_C7XV_FW_REGION_1_START_ADDRESS_L access per field reset 0x7E200000 — The FW Region 1 Start Address Low Register defines the start address bits 31 to 0 for the target Iam275_c7xv_wrap_0_main_0.soc_c7xv region 1 firewall.
  fields as CBASS_FW_IMSRAM32KX256E_MAIN_0_SLV_FW_REGION_0_START_ADDRESS_L
0x1838 CBASS_FW_IAM275_C7XV_WRAP_0_MAIN_0_SOC_C7XV_FW_REGION_1_END_ADDRESS_L access per field reset 0x7E23FFFF — The FW Region 1 End Address Low Register defines the end address bits 31 to 0 to include for the target Iam275_c7xv_wrap_0_main_0.soc_c7xv region 1 firewall.
  fields as CBASS_FW_IMSRAM32KX256E_MAIN_0_SLV_FW_REGION_0_END_ADDRESS_L
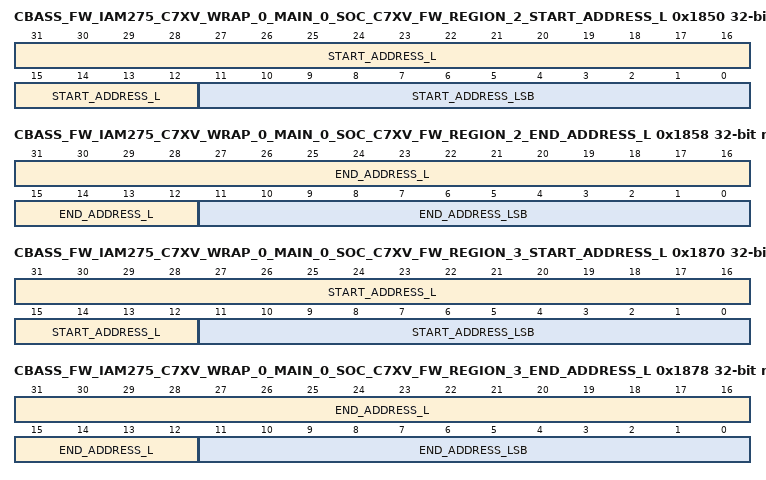
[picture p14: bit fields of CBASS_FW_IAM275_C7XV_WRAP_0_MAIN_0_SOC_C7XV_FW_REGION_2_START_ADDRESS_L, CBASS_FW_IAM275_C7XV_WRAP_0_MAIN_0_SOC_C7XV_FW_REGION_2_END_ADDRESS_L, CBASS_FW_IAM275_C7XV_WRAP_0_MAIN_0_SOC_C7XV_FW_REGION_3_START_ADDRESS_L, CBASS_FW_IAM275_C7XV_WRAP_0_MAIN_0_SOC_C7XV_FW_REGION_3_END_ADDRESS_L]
0x1850 CBASS_FW_IAM275_C7XV_WRAP_0_MAIN_0_SOC_C7XV_FW_REGION_2_START_ADDRESS_L access per field reset 0x7C000000 — The FW Region 2 Start Address Low Register defines the start address bits 31 to 0 for the target Iam275_c7xv_wrap_0_main_0.soc_c7xv region 2 firewall.
  fields as CBASS_FW_IMSRAM32KX256E_MAIN_0_SLV_FW_REGION_0_START_ADDRESS_L
0x1858 CBASS_FW_IAM275_C7XV_WRAP_0_MAIN_0_SOC_C7XV_FW_REGION_2_END_ADDRESS_L access per field reset 0x7C01FFFF — The FW Region 2 End Address Low Register defines the end address bits 31 to 0 to include for the target Iam275_c7xv_wrap_0_main_0.soc_c7xv region 2 firewall.
  fields as CBASS_FW_IMSRAM32KX256E_MAIN_0_SLV_FW_REGION_0_END_ADDRESS_L
0x1870 CBASS_FW_IAM275_C7XV_WRAP_0_MAIN_0_SOC_C7XV_FW_REGION_3_START_ADDRESS_L access per field reset 0x7C400000 — The FW Region 3 Start Address Low Register defines the start address bits 31 to 0 for the target Iam275_c7xv_wrap_0_main_0.soc_c7xv region 3 firewall.
  fields as CBASS_FW_IMSRAM32KX256E_MAIN_0_SLV_FW_REGION_0_START_ADDRESS_L
0x1878 CBASS_FW_IAM275_C7XV_WRAP_0_MAIN_0_SOC_C7XV_FW_REGION_3_END_ADDRESS_L access per field reset 0x7C403FFF — The FW Region 3 End Address Low Register defines the end address bits 31 to 0 to include for the target Iam275_c7xv_wrap_0_main_0.soc_c7xv region 3 firewall.
  fields as CBASS_FW_IMSRAM32KX256E_MAIN_0_SLV_FW_REGION_0_END_ADDRESS_L
0x1890 CBASS_FW_IAM275_C7XV_WRAP_0_MAIN_0_SOC_C7XV_FW_REGION_4_START_ADDRESS_L access per field reset 0x7C408000 — The FW Region 4 Start Address Low Register defines the start address bits 31 to 0 for the target Iam275_c7xv_wrap_0_main_0.soc_c7xv region 4 firewall.
  fields as CBASS_FW_IMSRAM32KX256E_MAIN_0_SLV_FW_REGION_0_START_ADDRESS_L
0x1898 CBASS_FW_IAM275_C7XV_WRAP_0_MAIN_0_SOC_C7XV_FW_REGION_4_END_ADDRESS_L access per field reset 0x7C40FFFF — The FW Region 4 End Address Low Register defines the end address bits 31 to 0 to include for the target Iam275_c7xv_wrap_0_main_0.soc_c7xv region 4 firewall.
  fields as CBASS_FW_IMSRAM32KX256E_MAIN_0_SLV_FW_REGION_0_END_ADDRESS_L
0x18B0 CBASS_FW_IAM275_C7XV_WRAP_0_MAIN_0_SOC_C7XV_FW_REGION_5_START_ADDRESS_L access per field reset 0x7C404000 — The FW Region 5 Start Address Low Register defines the start address bits 31 to 0 for the target Iam275_c7xv_wrap_0_main_0.soc_c7xv region 5 firewall.
  fields as CBASS_FW_IMSRAM32KX256E_MAIN_0_SLV_FW_REGION_0_START_ADDRESS_L
0x18B8 CBASS_FW_IAM275_C7XV_WRAP_0_MAIN_0_SOC_C7XV_FW_REGION_5_END_ADDRESS_L access per field reset 0x7C407FFF — The FW Region 5 End Address Low Register defines the end address bits 31 to 0 to include for the target Iam275_c7xv_wrap_0_main_0.soc_c7xv region 5 firewall.
  fields as CBASS_FW_IMSRAM32KX256E_MAIN_0_SLV_FW_REGION_0_END_ADDRESS_L
0x18D0 CBASS_FW_IAM275_C7XV_WRAP_0_MAIN_0_SOC_C7XV_FW_REGION_6_START_ADDRESS_L access per field reset 0x7C440000 — The FW Region 6 Start Address Low Register defines the start address bits 31 to 0 for the target Iam275_c7xv_wrap_0_main_0.soc_c7xv region 6 firewall.
  fields as CBASS_FW_IMSRAM32KX256E_MAIN_0_SLV_FW_REGION_0_START_ADDRESS_L
0x18D8 CBASS_FW_IAM275_C7XV_WRAP_0_MAIN_0_SOC_C7XV_FW_REGION_6_END_ADDRESS_L access per field reset 0x7C45FFFF — The FW Region 6 End Address Low Register defines the end address bits 31 to 0 to include for the target Iam275_c7xv_wrap_0_main_0.soc_c7xv region 6 firewall.
  fields as CBASS_FW_IMSRAM32KX256E_MAIN_0_SLV_FW_REGION_0_END_ADDRESS_L
0x18F0 CBASS_FW_IAM275_C7XV_WRAP_0_MAIN_0_SOC_C7XV_FW_REGION_7_START_ADDRESS_L access per field reset 0x7C460000 — The FW Region 7 Start Address Low Register defines the start address bits 31 to 0 for the target Iam275_c7xv_wrap_0_main_0.soc_c7xv region 7 firewall.
  fields as CBASS_FW_IMSRAM32KX256E_MAIN_0_SLV_FW_REGION_0_START_ADDRESS_L
0x18F8 CBASS_FW_IAM275_C7XV_WRAP_0_MAIN_0_SOC_C7XV_FW_REGION_7_END_ADDRESS_L access per field reset 0x7C47FFFF — The FW Region 7 End Address Low Register defines the end address bits 31 to 0 to include for the target Iam275_c7xv_wrap_0_main_0.soc_c7xv region 7 firewall.
  fields as CBASS_FW_IMSRAM32KX256E_MAIN_0_SLV_FW_REGION_0_END_ADDRESS_L
{0x1C00+0x20*i} CBASS_FW_IAM275_C7XV_WRAP_1_MAIN_0_SOC_C7XV_FW_REGION_{i}_CONTROL access not given (i=0..7) — The FW Region {i} Control Register defines the control fields for the target Iam275_c7xv_wrap_1_main_0.soc_c7xv region {i} firewall.
  fields as CBASS_FW_IMSRAM32KX256E_MAIN_0_SLV_FW_REGION_0_CONTROL
{0x1C04+0x20*i} CBASS_FW_IAM275_C7XV_WRAP_1_MAIN_0_SOC_C7XV_FW_REGION_{i}_PERMISSION_0 (i=0..7) — The FW Region {i} Permission 0 Register defines the permissions for the target Iam275_c7xv_wrap_1_main_0.soc_c7xv region {i} firewall.
  fields as CBASS_FW_IMSRAM32KX256E_MAIN_0_SLV_FW_REGION_0_PERMISSION_0
{0x1C08+0x20*i} CBASS_FW_IAM275_C7XV_WRAP_1_MAIN_0_SOC_C7XV_FW_REGION_{i}_PERMISSION_1 (i=0..7) — The FW Region {i} Permission 1 Register defines the permissions for the target Iam275_c7xv_wrap_1_main_0.soc_c7xv region {i} firewall.
  fields as CBASS_FW_IMSRAM32KX256E_MAIN_0_SLV_FW_REGION_0_PERMISSION_0
{0x1C0C+0x20*i} CBASS_FW_IAM275_C7XV_WRAP_1_MAIN_0_SOC_C7XV_FW_REGION_{i}_PERMISSION_2 (i=0..7) — The FW Region {i} Permission 2 Register defines the permissions for the target Iam275_c7xv_wrap_1_main_0.soc_c7xv region {i} firewall.
  fields as CBASS_FW_IMSRAM32KX256E_MAIN_0_SLV_FW_REGION_0_PERMISSION_0
0x1C10 CBASS_FW_IAM275_C7XV_WRAP_1_MAIN_0_SOC_C7XV_FW_REGION_0_START_ADDRESS_L access per field reset 0x7F000000 — The FW Region 0 Start Address Low Register defines the start address bits 31 to 0 for the target Iam275_c7xv_wrap_1_main_0.soc_c7xv region 0 firewall.
  fields as CBASS_FW_IMSRAM32KX256E_MAIN_0_SLV_FW_REGION_0_START_ADDRESS_L
{0x1C14+0x20*i} CBASS_FW_IAM275_C7XV_WRAP_1_MAIN_0_SOC_C7XV_FW_REGION_{i}_START_ADDRESS_H (i=0..7) — The FW Region {i} Start Address High Register defines the start address bits 47 to 32 for the target Iam275_c7xv_wrap_1_main_0.soc_c7xv region {i} firewall.
  fields as CBASS_FW_IMSRAM32KX256E_MAIN_0_SLV_FW_REGION_0_START_ADDRESS_H
0x1C18 CBASS_FW_IAM275_C7XV_WRAP_1_MAIN_0_SOC_C7XV_FW_REGION_0_END_ADDRESS_L access per field reset 0x7F1FFFFF — The FW Region 0 End Address Low Register defines the end address bits 31 to 0 to include for the target Iam275_c7xv_wrap_1_main_0.soc_c7xv region 0 firewall.
  fields as CBASS_FW_IMSRAM32KX256E_MAIN_0_SLV_FW_REGION_0_END_ADDRESS_L
{0x1C1C+0x20*i} CBASS_FW_IAM275_C7XV_WRAP_1_MAIN_0_SOC_C7XV_FW_REGION_{i}_END_ADDRESS_H (i=0..7) — The FW Region {i} End Address High Register defines the end address bits 47 to 32 to include for the target Iam275_c7xv_wrap_1_main_0.soc_c7xv region {i} firewall.
  fields as CBASS_FW_IMSRAM32KX256E_MAIN_0_SLV_FW_REGION_0_END_ADDRESS_H
0x1C30 CBASS_FW_IAM275_C7XV_WRAP_1_MAIN_0_SOC_C7XV_FW_REGION_1_START_ADDRESS_L access per field reset 0x7F200000 — The FW Region 1 Start Address Low Register defines the start address bits 31 to 0 for the target Iam275_c7xv_wrap_1_main_0.soc_c7xv region 1 firewall.
  fields as CBASS_FW_IMSRAM32KX256E_MAIN_0_SLV_FW_REGION_0_START_ADDRESS_L
0x1C38 CBASS_FW_IAM275_C7XV_WRAP_1_MAIN_0_SOC_C7XV_FW_REGION_1_END_ADDRESS_L access per field reset 0x7F23FFFF — The FW Region 1 End Address Low Register defines the end address bits 31 to 0 to include for the target Iam275_c7xv_wrap_1_main_0.soc_c7xv region 1 firewall.
  fields as CBASS_FW_IMSRAM32KX256E_MAIN_0_SLV_FW_REGION_0_END_ADDRESS_L
0x1C50 CBASS_FW_IAM275_C7XV_WRAP_1_MAIN_0_SOC_C7XV_FW_REGION_2_START_ADDRESS_L access per field reset 0x7D000000 — The FW Region 2 Start Address Low Register defines the start address bits 31 to 0 for the target Iam275_c7xv_wrap_1_main_0.soc_c7xv region 2 firewall.
  fields as CBASS_FW_IMSRAM32KX256E_MAIN_0_SLV_FW_REGION_0_START_ADDRESS_L
0x1C58 CBASS_FW_IAM275_C7XV_WRAP_1_MAIN_0_SOC_C7XV_FW_REGION_2_END_ADDRESS_L access per field reset 0x7D01FFFF — The FW Region 2 End Address Low Register defines the end address bits 31 to 0 to include for the target Iam275_c7xv_wrap_1_main_0.soc_c7xv region 2 firewall.
  fields as CBASS_FW_IMSRAM32KX256E_MAIN_0_SLV_FW_REGION_0_END_ADDRESS_L
0x1C70 CBASS_FW_IAM275_C7XV_WRAP_1_MAIN_0_SOC_C7XV_FW_REGION_3_START_ADDRESS_L access per field reset 0x7D400000 — The FW Region 3 Start Address Low Register defines the start address bits 31 to 0 for the target Iam275_c7xv_wrap_1_main_0.soc_c7xv region 3 firewall.
  fields as CBASS_FW_IMSRAM32KX256E_MAIN_0_SLV_FW_REGION_0_START_ADDRESS_L
0x1C78 CBASS_FW_IAM275_C7XV_WRAP_1_MAIN_0_SOC_C7XV_FW_REGION_3_END_ADDRESS_L access per field reset 0x7D403FFF — The FW Region 3 End Address Low Register defines the end address bits 31 to 0 to include for the target Iam275_c7xv_wrap_1_main_0.soc_c7xv region 3 firewall.
  fields as CBASS_FW_IMSRAM32KX256E_MAIN_0_SLV_FW_REGION_0_END_ADDRESS_L
0x1C90 CBASS_FW_IAM275_C7XV_WRAP_1_MAIN_0_SOC_C7XV_FW_REGION_4_START_ADDRESS_L access per field reset 0x7D408000 — The FW Region 4 Start Address Low Register defines the start address bits 31 to 0 for the target Iam275_c7xv_wrap_1_main_0.soc_c7xv region 4 firewall.
  fields as CBASS_FW_IMSRAM32KX256E_MAIN_0_SLV_FW_REGION_0_START_ADDRESS_L
0x1C98 CBASS_FW_IAM275_C7XV_WRAP_1_MAIN_0_SOC_C7XV_FW_REGION_4_END_ADDRESS_L access per field reset 0x7D40FFFF — The FW Region 4 End Address Low Register defines the end address bits 31 to 0 to include for the target Iam275_c7xv_wrap_1_main_0.soc_c7xv region 4 firewall.
  fields as CBASS_FW_IMSRAM32KX256E_MAIN_0_SLV_FW_REGION_0_END_ADDRESS_L
0x1CB0 CBASS_FW_IAM275_C7XV_WRAP_1_MAIN_0_SOC_C7XV_FW_REGION_5_START_ADDRESS_L access per field reset 0x7D404000 — The FW Region 5 Start Address Low Register defines the start address bits 31 to 0 for the target Iam275_c7xv_wrap_1_main_0.soc_c7xv region 5 firewall.
  fields as CBASS_FW_IMSRAM32KX256E_MAIN_0_SLV_FW_REGION_0_START_ADDRESS_L
0x1CB8 CBASS_FW_IAM275_C7XV_WRAP_1_MAIN_0_SOC_C7XV_FW_REGION_5_END_ADDRESS_L access per field reset 0x7D407FFF — The FW Region 5 End Address Low Register defines the end address bits 31 to 0 to include for the target Iam275_c7xv_wrap_1_main_0.soc_c7xv region 5 firewall.
  fields as CBASS_FW_IMSRAM32KX256E_MAIN_0_SLV_FW_REGION_0_END_ADDRESS_L
0x1CD0 CBASS_FW_IAM275_C7XV_WRAP_1_MAIN_0_SOC_C7XV_FW_REGION_6_START_ADDRESS_L access per field reset 0x7D440000 — The FW Region 6 Start Address Low Register defines the start address bits 31 to 0 for the target Iam275_c7xv_wrap_1_main_0.soc_c7xv region 6 firewall.
  fields as CBASS_FW_IMSRAM32KX256E_MAIN_0_SLV_FW_REGION_0_START_ADDRESS_L
0x1CD8 CBASS_FW_IAM275_C7XV_WRAP_1_MAIN_0_SOC_C7XV_FW_REGION_6_END_ADDRESS_L access per field reset 0x7D45FFFF — The FW Region 6 End Address Low Register defines the end address bits 31 to 0 to include for the target Iam275_c7xv_wrap_1_main_0.soc_c7xv region 6 firewall.
  fields as CBASS_FW_IMSRAM32KX256E_MAIN_0_SLV_FW_REGION_0_END_ADDRESS_L
0x1CF0 CBASS_FW_IAM275_C7XV_WRAP_1_MAIN_0_SOC_C7XV_FW_REGION_7_START_ADDRESS_L access per field reset 0x7D460000 — The FW Region 7 Start Address Low Register defines the start address bits 31 to 0 for the target Iam275_c7xv_wrap_1_main_0.soc_c7xv region 7 firewall.
  fields as CBASS_FW_IMSRAM32KX256E_MAIN_0_SLV_FW_REGION_0_START_ADDRESS_L
0x1CF8 CBASS_FW_IAM275_C7XV_WRAP_1_MAIN_0_SOC_C7XV_FW_REGION_7_END_ADDRESS_L access per field reset 0x7D47FFFF — The FW Region 7 End Address Low Register defines the end address bits 31 to 0 to include for the target Iam275_c7xv_wrap_1_main_0.soc_c7xv region 7 firewall.
  fields as CBASS_FW_IMSRAM32KX256E_MAIN_0_SLV_FW_REGION_0_END_ADDRESS_L
